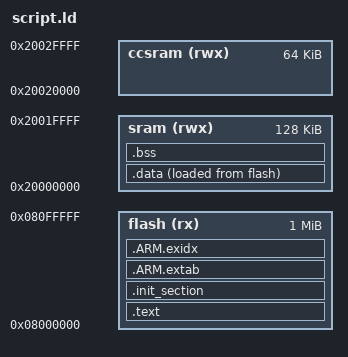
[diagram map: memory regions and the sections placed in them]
MEMORY
{
    flash (rx)   : ORIGIN = 0x08000000, LENGTH = 1024K
    sram (rwx)   : ORIGIN = 0x20000000, LENGTH = 128K
    ccsram (rwx) : ORIGIN = 0x20020000, LENGTH = 64K
}

OUTPUT_ARCH(arm)
ENTRY(__start)
EXTERN(_vectors)
EXTERN(abort)

SECTIONS
{
	.text : {
		_stext = ABSOLUTE(.);
		*(.vectors)
		*(.text .text.*)
		*(.fixup)
		*(.gnu.warning)
		*(.rodata .rodata.*)
		*(.gnu.linkonce.t.*)
		*(.got)
		*(.gcc_except_table)
		*(.gnu.linkonce.r.*)
		_etext = ABSOLUTE(.);
	} > flash

	.init_section : {
		_sinit = ABSOLUTE(.);
		KEEP(*(.init_array .init_array.*))
		_einit = ABSOLUTE(.);
	} > flash

	.ARM.extab : {
		*(.ARM.extab*)
	} > flash

	__exidx_start = ABSOLUTE(.);
	.ARM.exidx : {
		*(.ARM.exidx*)
	} > flash
	__exidx_end = ABSOLUTE(.);

	_eronly = ABSOLUTE(.);

	.data : {
		_sdata = ABSOLUTE(.);
		*(.data .data.*)
		*(.gnu.linkonce.d.*)
		CONSTRUCTORS
		_edata = ABSOLUTE(.);
	} > sram AT > flash

	.bss : {
		_sbss = ABSOLUTE(.);
		*(.bss .bss.*)
		*(.gnu.linkonce.b.*)
		*(COMMON)
		. = ALIGN(4);
		_ebss = ABSOLUTE(.);
	} > sram
}
